# NUC505_v1 register map
File version: 1.0
Registers are 32-bit, read-write, reset 0x0 unless marked. A register's access mark holds for its fields unless they carry their own. Offsets are from the block's base; [hi:lo] are bit positions; {n}, {i} and the like mark numbered series.

## SPIM — SPIM Register Map
Base 0x40007000
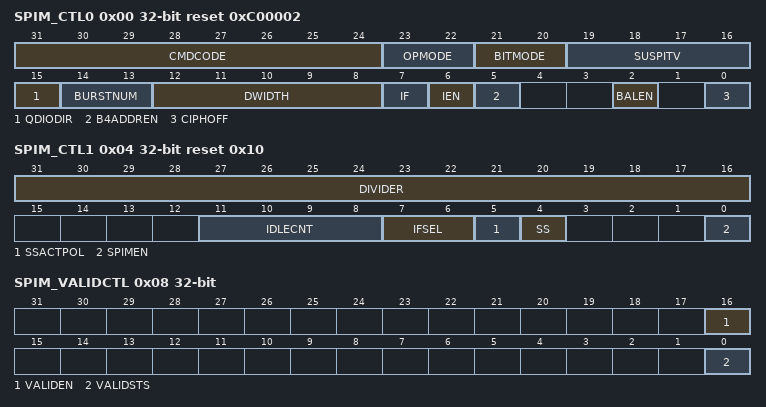
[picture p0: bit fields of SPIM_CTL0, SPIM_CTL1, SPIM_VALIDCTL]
0x00 SPIM_CTL0 reset 0xC00002 — Control and Status Register 0
  [31:24] CMDCODE — Page Program Command Code. Note1: Quad mode of SPI Flash must be enabled first by I/O mode before using quad page program/quad read commands. Note2: See support list for SPI Flash which support these command codes. Note3: For TYPE_1, TYPE_2, and TYPE_3 program flows, refer to Figure 6.133, Figure 6.134, and Figure 6.135.
    2=Page program (Used for DMA Write mode); 3=Standard read (Used for DMA Read/DMM mode); 11=Fast read (Used for DMA Read/DMM mode); 50=Quad page program with TYPE_1 program flow (Used for DMA Write mode); 56=Quad page program with TYPE_2 program flow (Used for DMA Write mode); 59=Fast dual read (Used for DMA Read/DMM mode); 64=Quad page program with TYPE_3 program flow (Used for DMA Write mode); 235=Quad read (Used for DMA Read/DMM mode)
  [23:22] OPMODE — SPI Function Operation Mode. Note: In DMA Write mode, hardware will send just one page program command per operation. Users must take care of cross-page cases.
    0=I/O mode; 1=DMA Write mode; 2=DMA Read mode; 3=Direct Memory Map (DMM) mode (Default)
  [21:20] BITMODE — SPI Interface Bit Mode. Note: Only used for I/O mode.
    0=Standard mode; 1=Dual mode; 2=Quad mode
  [19:16] SUSPITV — Suspend Interval. Note: Only used for I/O mode.
    0=2 SCLK clock cycles; 1=3 SCLK clock cycles; 14=16 SCLK clock cycles; 15=17 SCLK clock cycles
  [15] QDIODIR — SPI Interface Direction Select for Quad/Dual Mode. Note: Only used for I/O mode.
    0=Interface signals are input; 1=Interface signals are output
  [14:13] BURSTNUM — Transmit/Receive Burst Number. This field specifies how many transmit/receive transactions should be executed continuously in one transfer. Note: Only used for I/O Mode.
    0=Only one transmit/receive transaction will be executed in one transfer; 1=Two successive transmit/receive transactions will be executed in one transfer; 2=Three successive transmit/receive transactions will be executed in one transfer; 3=Four successive transmit/receive transactions will be executed in one transfer
  [12:8] DWIDTH — Transmit/Receive Bit Length. This field specifies how many bits are transmitted/received in one transmit/receive transaction. Note1: Only used for I/O mode. Note2: Only 8-, 16-, 24-, and 32-bit are allowed. Other bit length will result in incorrect transfer.
    7=8 bits; 15=16 bits; 23=24 bits; 31=32 bits
  [7] IF — Interrupt Flag. Write Operation:
    0=No effect. The transfer has not finished yet; 1=Write 1 to clear. The transfer has done
  [6] IEN — Interrupt Enable Control
    0=SPIM Interrupt Disabled; 1=SPIM Interrupt Enabled
  [5] B4ADDREN — 4-byte Address Mode Enable Control. Note: Used for DMA Write/DMA Read/DMM mode.
    0=4-byte address mode Disabled; 1=4-byte address mode Enabled
  [2] BALEN — Balance the AHB Control Time Between Cipher Enable and Disable Control. When cipher is enabled, the AHB control signal will delay some time caused by the encoding or decoding calculation. Therefore, if set BALEN to 1, it will make the AHB signal processing time with cipher disabled be equal to that with cipher enabled. Note: Only useful when cipher is disabled.
  [0] CIPHOFF — Cipher Disable Control. Note1: Cipher function only can be disabled. If user wants to enable cipher function after disabled processing, the chip must be reset again. Note2: If there is not any key in the chip, the cipher will be disabled automatically. Note3: In ICE mode, the cipher will be disabled automatically.
    0=Cipher function Enabled; 1=Cipher function Disabled
0x04 SPIM_CTL1 reset 0x10 — Control Register 1
  [31:16] DIVIDER — Clock Divider Register. The value in this field is the frequency divider of the system clock to generate the serial clock on the output SPIM_CLK pin. The desired frequency is obtained according to the following equation: . Note: When set DIVIDER to zero, the frequency of SPIM_CLK will be equal to the frequency of SYS_CLK.
  [11:8] IDLECNT — Idle Interval. In DMM mode, IDLECNT is set to control the minimum idle time between two SPI Flash accesses. Note: Only used for DMM mode.
  [7:6] IFSEL — Device/Slave Interface Select. Note: MCP and MCP64 only can be referenced by MCP SPI Flash pad location.
    0=SPI Interface from GPIO; 1=SPI Interface from MCP; 2=SPI Interface from MCP64
  [5] SSACTPOL — Slave Select Active Level. It defines the active level of device/slave select signal (SPIM_SS).
    0=The SPIM_SS slave select signal is Active Low; 1=The SPIM_SS slave select signal is Active High
  [4] SS — Slave Select Active Enable Control. Note: This interface can only drive one device/slave at a given time. Therefore, the slave selects of the selected device must be set to its active level before starting any read or write transfer.
    0=SPIM_SS is in active level; 1=SPIM_SS is in inactive level
  [0] SPIMEN — Go and Busy Status. Write Operation: Note: All registers should be set before writing 1 to the SPIMEN bit. When a transfer is in progress, you should not write to any register of this peripheral.
    0=No effect. The transfer has done; 1=Start the transfer. This bit remains set during the transfer and is automatically cleared after transfer finished. The transfer has not finished yet
0x08 SPIM_VALIDCTL — Validation Check Register
  [16] VALIDEN — Validation Enable Bit. Setting this bit to enable the validation function. The function can check whether the code in SPI Flash is valid or not.
    0=1 (Rising Edge) = Enable the validation and clear the VALIDSTS bit; 1=0 (Falling Edge) = Disable the validation and update the VALIDSTS bit
  [0] VALIDSTS — Validation Status Bit. This bit will be updated when the VALIDEN bit changes. Note: Write 0 to clear it to 0.
    0=Code in SPI Flash is not valid; 1=Code in SPI Flash is valid
0x0C SPIM_RXCLKDLY — Rx Clock Delay Control Register
  [31:29] DLYSEL — Rx Sample Clock Source Delay Chain Select
    0=Not Delay; 1=Select sample clock through 2 Delay Cell; 2=Select sample clock through 4 Delay Cell; 3=Select sample clock through 6 Delay Cell; 7=Select sample clock through 14 Delay Cell
{0x10+4i} SPIM_RX{i} ro (i=0..3) — Data Receive Register {i}
  [31:0] RX — Data Receive Register. The Data Receive Registers hold the received data of the last executed transfer. Number of valid RX registers is specified in SPIM_CTL0[BURSTNUM]. If BURSTNUM 0, received data are held in the most significant RX register first. Number of valid-bit is specified in SPIM_CTL0[DWIDTH]. If DWIDTH is 16, 24, or 32, received data are held in the least significant byte of RX register first. In a byte, received data are held in the most significant bit of RX register first.
{0x20+4i} SPIM_TX{i} (i=0..3) — Data Transmit Register {i}
  [31:0] TX — Data Transmit Register. The Data Transmit Registers hold the data to be transmitted in next transfer. Number of valid TX registers is specified in SPIM_CTL0[BURSTNUM]. If BURSTNUM 0, data are transmitted in the most significant TX register first. Number of valid-bit is specified in SPIM_CTL0[DWIDTH]. If DWIDTH is 16, 24, or 32, data are transmitted in the least significant byte of TX register first. In a byte, data are transmitted in the most significant bit of TX register first.
0x30 SPIM_SRAMADDR — SRAM Memory Address Register
  [31:0] ADDR — SRAM Memory Address. For DMA Read mode, this is the destination address for DMA transfer. For DMA Write mode, this is the source address for DMA transfer. Note: This address must be word-aligned.
0x34 SPIM_DMATBCNT — DMA Transfer Byte Count Register
  [23:0] CNT — DMA Transfer Byte Count Register. It indicates the transfer length for DMA process. Note: The unit for counting is byte. Note2: The number must be the multiple of 4.
0x38 SPIM_FADDR — SPI Flash Address Register
  [31:0] ADDR — SPI Flash Address Register. For DMA Read mode, this is the source address for DMA transfer. For DMA Write mode, this is the destination address for DMA transfer. Note: This address must be word-aligned.
